# GD32F20x_CL register map
File version: 1.0
CPU: CM3 r2p1, little endian, no MPU, no FPU, 4 interrupt priority bits
Registers are 32-bit, read-write, reset 0x0 unless marked. A register's access mark holds for its fields unless they carry their own. Offsets are from the block's base; [hi:lo] are bit positions; {n}, {i} and the like mark numbered series.

## NVIC — Nested Vectored Interrupt Controller
Base 0xE000E000
0x04 ICTR ro — Interrupt Controller Type Register
  [3:0] INTLINESNUM — Total number of interrupt lines in groups
{0x100+4i} ISER{i} (i=0..2) — Interrupt Set-Enable Register
  [31:0] SETENA
{0x180+4i} ICER{i} (i=0..2) — Interrupt Clear-Enable Register
  [31:0] CLRENA
{0x200+4i} ISPR{i} (i=0..2) — Interrupt Set-Pending Register
  [31:0] SETPEND
{0x280+4i} ICPR{i} (i=0..2) — Interrupt Clear-Pending Register
  [31:0] CLRPEND
{0x300+4i} IABR{i} ro (i=0..2) — Interrupt Active Bit Register
  [31:0] ACTIVE
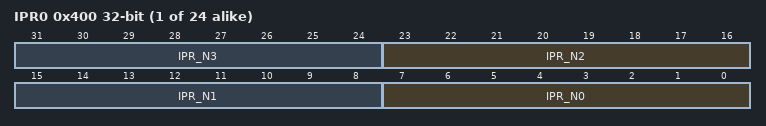
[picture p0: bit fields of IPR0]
{0x400+4i} IPR{i} (i=0..23) — Interrupt Priority Register
  [8n+7:8n] IPR_N{n} (n=0..3)
0xF00 STIR wo — Software Triggered Interrupt Register
  [8:0] INTID — interrupt to be triggered

## PMU — Power management unit
Base 0x40007000
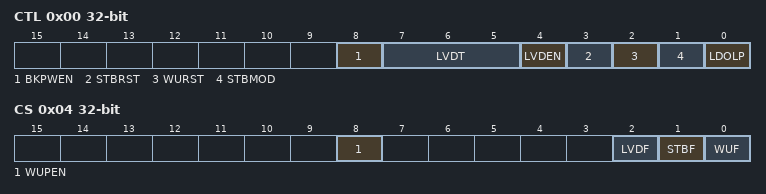
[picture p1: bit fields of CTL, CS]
0x00 CTL — power control register
  [8] BKPWEN — Backup Domain Write Enable
  [7:5] LVDT — Low Voltage Detector Threshold
  [4] LVDEN — Low Voltage Detector Enable
  [3] STBRST — Standby Flag Reset
  [2] WURST — Wakeup Flag Reset
  [1] STBMOD — Standby Mode
  [0] LDOLP — LDO Low Power Mode
0x04 CS access per field — power control/status register
  [8] WUPEN rw — Enable WKUP pin
  [2] LVDF ro — Low Voltage Detector Status Flag
  [1] STBF ro — Standby flag
  [0] WUF ro — Wakeup flag

## RTC — Real-time clock
Base 0x40002800
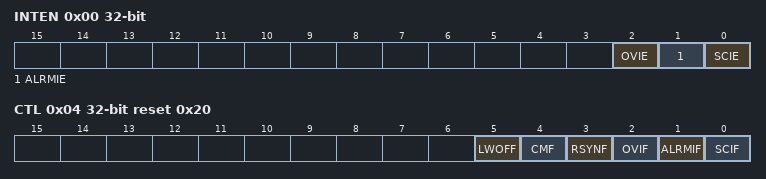
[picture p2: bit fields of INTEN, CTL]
0x00 INTEN — RTC interrupt enable register
  [2] OVIE — Overflow interrupt enable
  [1] ALRMIE — Alarm interrupt enable
  [0] SCIE — Second interrupt
0x04 CTL access per field reset 0x20 — control register
  [5] LWOFF ro — Last write operation finished flag
  [4] CMF rw — Configuration mode flag
  [3] RSYNF rw — Registers synchronized flag
  [2] OVIF rw — Overflow interrupt flag
  [1] ALRMIF rw — Alarm interrupt flag
  [0] SCIF rw — Sencond interrupt flag
0x08 PSCH wo — RTC prescaler high register
  [3:0] PSC — RTC prescaler value high
0x0C PSCL wo reset 0x8000 — RTC prescaler low register
  [15:0] PSC — RTC prescaler value low
0x10 DIVH ro — RTC divider high register
  [3:0] DIV — RTC divider value high
0x14 DIVL ro reset 0x8000 — RTC divider low register
  [15:0] DIV — RTC divider value low
0x18 CNTH — RTC counter high register
  [15:0] CNT — RTC counter value high
0x1C CNTL — RTC counter low register
  [15:0] CNT — RTC conuter value low
0x20 ALRMH wo reset 0xFFFF — Alarm high register
  [15:0] ALRM — Alarm value high
0x24 ALRML wo reset 0xFFFF — RTC alarm low register
  [15:0] ALRM — alarm value low

## SPI0 — Serial peripheral interface
Base 0x40013000
Same registers: SPI1 0x40003800, SPI2 0x40003C00
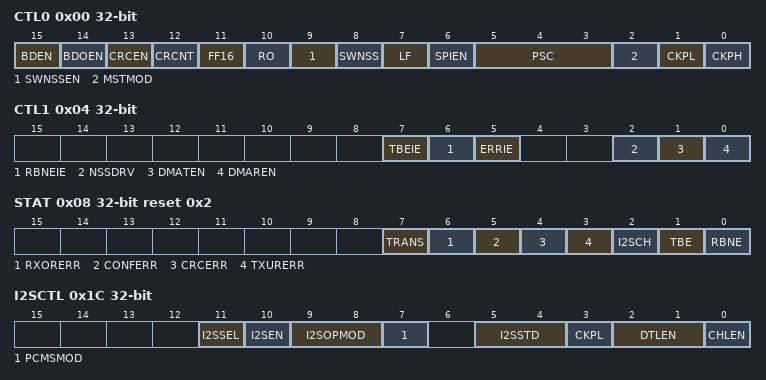
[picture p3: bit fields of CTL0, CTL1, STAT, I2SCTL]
0x00 CTL0 — control register 0
  [15] BDEN — Bidirectional enable
  [14] BDOEN — Bidirectional Transmit output enable
  [13] CRCEN — CRC Calculation Enable
  [12] CRCNT — CRC Next Transfer
  [11] FF16 — Data frame format
  [10] RO — Receive only
  [9] SWNSSEN — NSS Software Mode Selection
  [8] SWNSS — NSS Pin Selection In NSS Software Mode
  [7] LF — LSB First Mode
  [6] SPIEN — SPI enable
  [5:3] PSC — Master Clock Prescaler Selection
  [2] MSTMOD — Master Mode Enable
  [1] CKPL — Clock polarity Selection
  [0] CKPH — Clock Phase Selection
0x04 CTL1 — control register 1
  [7] TBEIE — Tx buffer empty interrupt enable
  [6] RBNEIE — RX buffer not empty interrupt enable
  [5] ERRIE — Error interrupt enable
  [2] NSSDRV — Drive NSS Output
  [1] DMATEN — Transmit Buffer DMA Enable
  [0] DMAREN — Rx buffer DMA enable
0x08 STAT access per field reset 0x2 — status register
  [7] TRANS ro — Transmitting On-going Bit
  [6] RXORERR ro — Reception Overrun Error Bit
  [5] CONFERR ro — SPI Configuration error
  [4] CRCERR rw — SPI CRC Error Bit
  [3] TXURERR ro — Transmission underrun error bit
  [2] I2SCH ro — I2S channel side
  [1] TBE ro — Transmit Buffer Empty
  [0] RBNE ro — Receive Buffer Not Empty
0x0C DATA
  [15:0] DATA — Data transfer register
0x10 CRCPOLY reset 0x7 — CRC polynomial register
  [15:0] CPR
0x14 RCRC ro — RX CRC register
  [15:0] RCR
0x18 TCRC ro — TX CRC register
  [15:0] TCR — Tx CRC register
0x1C I2SCTL — I2S control register
  [11] I2SSEL — I2S mode selection
  [10] I2SEN — I2S Enable
  [9:8] I2SOPMOD — I2S operation mode
  [7] PCMSMOD — PCM frame synchronization mode
  [5:4] I2SSTD — I2S standard selection
  [3] CKPL — Idle state clock polarity
  [2:1] DTLEN — Data length
  [0] CHLEN — Channel length (number of bits per audio channel)
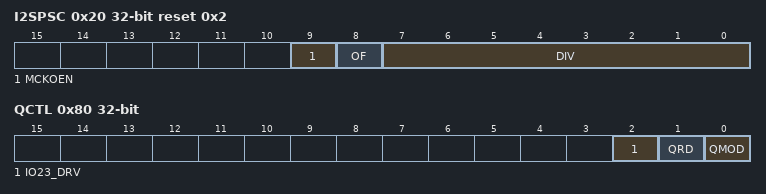
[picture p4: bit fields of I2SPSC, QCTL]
0x20 I2SPSC reset 0x2 — I2S prescaler register
  [9] MCKOEN — I2S_MCK output enable
  [8] OF — Odd factor for the prescaler
  [7:0] DIV — Dividing factor for the prescaler
0x80 QCTL — Quad-SPI mode control register
  [2] IO23_DRV — Drive IO2 and IO3 enable
  [1] QRD — Quad-SPI mode read select
  [0] QMOD — Quad-SPI mode enable
